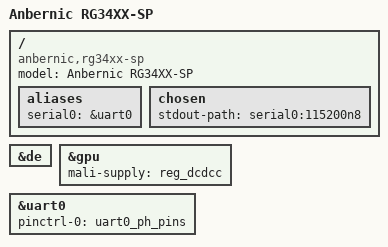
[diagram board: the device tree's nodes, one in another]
// SPDX-License-Identifier: (GPL-2.0-only OR BSD-2-Clause)
/*
 * Copyright (C) 2024 Ryan Walklin <ryan@testtoast.com>.
 * Copyright (C) 2024 Chris Morgan <macroalpha82@gmail.com>.
 * Copyright (C) 2025 RG34XXSP Armbian Port Project.
 */

/dts-v1/;
#include "sun50i-h616.dtsi"
#include "sun50i-h616-cpu-opp.dtsi"

/ {
	model = "Anbernic RG34XX-SP";
	compatible = "anbernic,rg34xx-sp", "allwinner,sun50i-h700";
	
	aliases {
		serial0 = &uart0;
	};
	
	chosen {
		stdout-path = "serial0:115200n8";
	};
};

&de {
	status = "okay";
};

&gpu {
	mali-supply = <&reg_dcdcc>;
	status = "okay";
};

&uart0 {
	pinctrl-names = "default";
	pinctrl-0 = <&uart0_ph_pins>;
	status = "okay";
};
